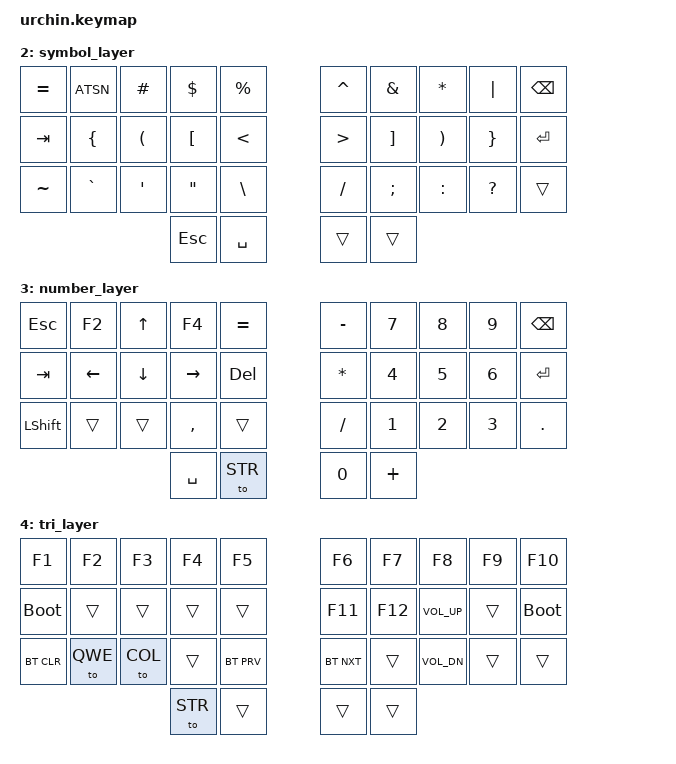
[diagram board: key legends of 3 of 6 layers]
// Copyright (c) 2022 The ZMK Contributors
// SPDX-License-Identifier: MIT

#include <behaviors.dtsi>
#include <dt-bindings/zmk/keys.h>
#include <dt-bindings/zmk/bt.h>
#include <dt-bindings/zmk/outputs.h>

// Home row mods macro
#define HRML(k1,k2,k3,k4) &ht LGUI k1 &ht LALT k2 &ht LCTRL k3 &ht LSHIFT k4
#define HRMR(k1,k2,k3,k4) &ht RSHIFT k1 &ht RCTRL k2 &ht RALT k3 &ht RGUI k4

#define STR 0
#define QWE 1
#define SYM 2
#define NUM 3
#define ADM 4
#define COL 5

/ {
    behaviors {
        ht: hold_tap {
            label = "hold_tap";
            compatible = "zmk,behavior-hold-tap";
            #binding-cells = <2>;
            flavor = "tap-preferred";
            tapping-term-ms = <220>;
            quick-tap-ms = <150>;
            global-quick-tap;
            bindings = <&kp>, <&kp>;
        };
        mo_to: behavior_mo_to {
            compatible = "zmk,behavior-hold-tap";
            #binding-cells = <2>;
            flavor = "hold-preferred";
            tapping-term-ms = <200>;
            bindings = <&mo>, <&to>;
        };
    };

    combos {
        compatible = "zmk,combos";
        combo_adm_layer {
            timeout-ms = <50>;
            key-positions = <29 32>;
            bindings = <&to ADM>;
        };
        combo_caps_lock {
           timeout-ms = <50>;
           key-positions = <13 16>;
           bindings = <&kp CAPS>;
        };
    };

    keymap {
        compatible = "zmk,keymap";
        strdy_layer {
            bindings = <
        //╭──────────┬──────────┬──────────┬──────────┬──────────╮   ╭──────────┬──────────┬──────────┬──────────┬──────────╮
        //│  V       │  M       │  L       │  C       │  P       │   │  X       │  F       │  O       │    U     |BACKSPACE │
            &kp V      &kp M      &kp L      &kp C      &kp P          &kp X      &kp F      &kp O       &kp U     &kp BSPC
        //├──────────┼──────────┼──────────┼──────────┼──────────┤   ├──────────┼──────────┼──────────┼──────────┼──────────┤
        //│  S       │  T       │  R       │  D       │  Y       │   │    J     │  N       │    A     │    E     │    I     │
            HRML(S,        T,         R,         D)     &kp Y           &kp J     HRMR(N,        A,        E,         I)
        //├──────────┼──────────┼──────────┼──────────┼──────────┤   ├──────────┼──────────┼──────────┼──────────┼──────────┤
        //│  Z       │  K       │  Q       │  G       │  W       │   │  B       │  H       │   , -    │   . !    │   / _    │
            &kp Z      &kp K      &kp Q      &kp G      &kp W         &kp B      &kp H  &ht MINUS COMMA &ht EXCL DOT &ht UNDERSCORE FSLH
        //╰──────────┴──────────┴──────────┼──────────┼──────────┤   ├──────────┼──────────┼──────────┴──────────┴──────────╯
                                             &kp ESC     &kp SPC  &mo_to SYM NUM  &ht COLON SEMI
        //                                 ╰──────────┴──────────╯   ╰──────────┴──────────╯
            >;
        };

        qwerty_layer {
            bindings = <
        //╭──────────┬──────────┬──────────┬──────────┬──────────╮   ╭──────────┬──────────┬──────────┬──────────┬──────────╮
        //│  Q       │  W       │  E       │  R       │  T       │   │  Y       │  U       │  I       │  O       │  P       │
            &kp Q      &kp W      &kp E      &kp R      &kp T          &kp Y      &kp U      &kp I      &kp O      &kp P
        //├──────────┼──────────┼──────────┼──────────┼──────────┤   ├──────────┼──────────┼──────────┼──────────┼──────────┤
        //│  A       │  S       │  D       │  F       │  G       │   │  H       │  J       │  K       │  L       │BACKSPACE │
            &kp A     HRML(S,         D,         F,         G)         &kp H        HRMR(J,        K,         L,    BSPC)
        //├──────────┼──────────┼──────────┼──────────┼──────────┤   ├──────────┼──────────┼──────────┼──────────┼──────────┤
        //│  Z       │  X       │  C       │  V       │  B       │   │  N       │  M       │ ,        │ .        │ ENTER    │
            &kp Z      &kp X      &kp C      &kp V      &kp B          &kp N      &kp M      &kp COMMA  &kp DOT    &kp ENTER
        //╰──────────┴──────────┴──────────┼──────────┼──────────┤   ├──────────┼──────────┼──────────┴──────────┴──────────╯
                                             &kp ESC     &kp SPC    &mo_to SYM NUM &ht COLON SEMI
        //                                 ╰──────────┴──────────╯   ╰──────────┴──────────╯
            >;
        };

        symbol_layer {
            bindings = <
        //╭──────────┬──────────┬──────────┬──────────┬──────────╮   ╭──────────┬──────────┬──────────┬──────────┬──────────╮
        //│ =        │  @       │  #       │  $       │  %       │   │ ^        │ &        │ *        │ |        │BACKSPACE |
          &kp EQUAL    &kp ATSN   &kp HASH  &kp DOLLAR &kp PRCNT       &kp CARET  &kp AMPS   &kp STAR   &kp PIPE    &kp BSPC
        //├──────────┼──────────┼──────────┼──────────┼──────────┤   ├──────────┼──────────┼──────────┼──────────┼──────────┤
        //│ TAB      │   {      │   (      │    [     │   <      |   |    >     │   ]      │    )     │    }     │   ENTER  │
           &kp TAB    &kp LBRC    &kp LPAR   &kp LBKT     &kp LT         &kp GT   &kp RBKT   &kp RPAR    &kp RBRC  &kp ENTER
        //├──────────┼──────────┼──────────┼──────────┼──────────┤   ├──────────┼──────────┼──────────┼──────────┼──────────┤
        //│   ~      │    `     │    '     │    "     │    \     │   │    /     │    ;     │    :     │    ?     │          │
           &kp TILDE   &kp GRAVE  &kp SQT    &kp DQT    &kp BSLH       &kp FSLH   &kp SEMI   &kp COLON  &kp QMARK  &trans 
        //╰──────────┴──────────┴──────────┼──────────┼──────────┤   ├──────────┼──────────┼──────────┴──────────┴──────────╯
                                             &kp ESC     &kp SPC        &trans     &trans
        //                                 ╰──────────┴──────────╯   ╰──────────┴──────────╯
            >;
        };

        number_layer {
            bindings = <
        //╭──────────┬──────────┬──────────┬──────────┬──────────╮   ╭──────────┬──────────┬──────────┬──────────┬──────────╮
        //│  ESC     │   F2     │   UP     │    F4    │    =     │   │    -     │    7     │    8     │    9     │  BKSP    │
             &kp ESC     &kp F2    &kp UP    &kp F4    &kp EQUAL       &kp MINUS   &kp N7    &kp N8      &kp N9    &kp BKSP
        //├──────────┼──────────┼──────────┼──────────┼──────────┤   ├──────────┼──────────┼──────────┼──────────┼──────────┤
        //│  TAB     │  LEFT    │  DOWN    │  RIGHT   │  DEL     │   │   *      │    4     │    5     │    6     │  ENTER   │
            &kp TAB    &kp LEFT   &kp DOWN   &kp RIGHT  &kp DEL       &kp ASTRK    &kp N4     &kp N5     &kp N6    &kp ENTER
        //├──────────┼──────────┼──────────┼──────────┼──────────┤   ├──────────┼──────────┼──────────┼──────────┼──────────┤
        //│ LSHIFT   │          │          │     ,    │          │   │    /     │    1     │    2     │    3     │    .     │
           &kp LSHIFT   &trans     &trans   &kp COMMA   &trans         &kp FSLH  &kp N1      &kp N2     &kp N3     &kp DOT
        //╰──────────┴──────────┴──────────┼──────────┼──────────┤   ├──────────┼──────────┼──────────┴──────────┴──────────╯
                                             &kp SPC     &to STR        &kp N0    &kp PLUS
        //                                 ╰──────────┴──────────╯   ╰──────────┴──────────╯
            >;
        };

        tri_layer {
            bindings = <
                &kp F1      &kp F2 &kp F3 &kp F4 &kp F5			    &kp F6     &kp F7  &kp F8  &kp F9 &kp F10
		&bootloader &trans &trans &trans &trans                     &kp F11    &kp F12 &kp K_VOL_UP &trans &bootloader
		&bt BT_CLR  &to QWE &to COL &trans &bt BT_PRV    	    &bt BT_NXT &trans  &kp K_VOL_DN  &trans &trans
					  &to STR  &trans 		    &trans &trans 
            >;
        };

         default_layer {
            bindings = <
        //╭──────────┬──────────┬──────────┬──────────┬──────────╮   ╭──────────┬──────────┬──────────┬──────────┬──────────╮
        //│  Q       │  W       │  F       │  P       │  G       │   │  J       │  L       │  U       │  Y       |BACKSPACE │
            &kp Q      &kp W      &kp F      &kp P      &kp G          &kp J      &kp L      &kp U      &kp Y      &kp BSPC
        //├──────────┼──────────┼──────────┼──────────┼──────────┤   ├──────────┼──────────┼──────────┼──────────┼──────────┤
        //│  A       │  R       │  S       │  T       │  D       │   │  H       │  N       │  E       │  I       │  O       │
            HRML(A,        R,         S,         T)     &kp D          &kp H      HRMR(N,        E,        I,         O)
        //├──────────┼──────────┼──────────┼──────────┼──────────┤   ├──────────┼──────────┼──────────┼──────────┼──────────┤
        //│  Z       │  X       │  C       │  V       │  B       │   │  K       │  M       │ , -      │ . !      │  /  _    │
            &kp Z      &kp X      &kp C      &kp V      &kp B         &kp K    &kp M  &ht MINUS COMMA  &ht EXCL DOT    &ht UNDERSCORE FSLH
        //╰──────────┴──────────┴──────────┼──────────┼──────────┤   ├──────────┼──────────┼──────────┴──────────┴──────────╯
                                             &kp ESC     &kp SPC     &mo_to SYM NUM  &ht COLON SEMI
        //                                 ╰──────────┴──────────╯   ╰──────────┴──────────╯
            >;
        };
    };
};
